VERSION ""

NS_ :

BS_:

BU_: XXX

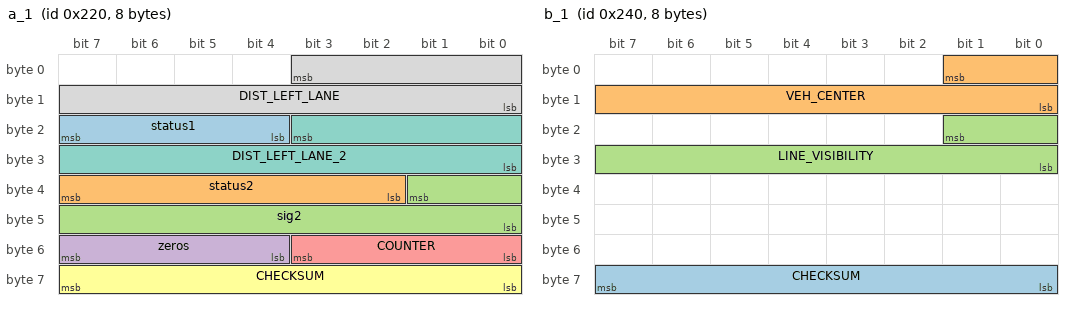
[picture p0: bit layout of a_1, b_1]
BO_ 544 a_1: 8 XXX
 SG_ status1 : 23|4@0+ (1,0) [0|15] "" XXX
 SG_ status2 : 39|6@0+ (1,0) [0|15] "" XXX
 SG_ sig2 : 33|10@0+ (1,0) [0|255] "" XXX
 SG_ zeros : 55|4@0+ (1,0) [0|15] "" XXX
 SG_ COUNTER : 51|4@0+ (1,0) [0|15] "" XXX
 SG_ CHECKSUM : 63|8@0+ (1,0) [0|255] "" XXX
 SG_ DIST_LEFT_LANE_2 : 19|12@0+ (1,0) [0|1] "" XXX
 SG_ DIST_LEFT_LANE : 3|12@0+ (1,0) [0|1] "" XXX

BO_ 576 b_1: 8 XXX
 SG_ CHECKSUM : 63|8@0+ (1,0) [0|255] "" XXX
 SG_ VEH_CENTER : 1|10@0+ (1,0) [0|1] "" XXX
 SG_ LINE_VISIBILITY : 17|10@0+ (1,0) [0|1] "" XXX

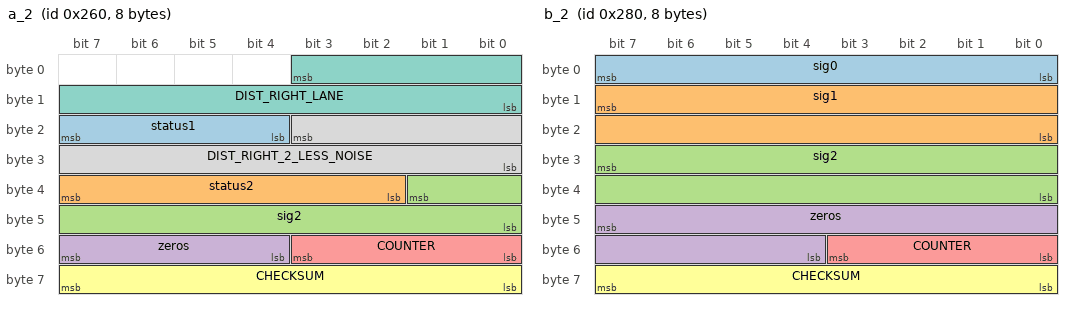
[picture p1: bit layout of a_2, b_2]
BO_ 608 a_2: 8 XXX
 SG_ status1 : 23|4@0+ (1,0) [0|15] "" XXX
 SG_ status2 : 39|6@0+ (1,0) [0|15] "" XXX
 SG_ sig2 : 33|10@0+ (1,0) [0|255] "" XXX
 SG_ zeros : 55|4@0+ (1,0) [0|15] "" XXX
 SG_ COUNTER : 51|4@0+ (1,0) [0|15] "" XXX
 SG_ CHECKSUM : 63|8@0+ (1,0) [0|255] "" XXX
 SG_ DIST_RIGHT_LANE : 3|12@0+ (1,0) [0|1] "" XXX
 SG_ DIST_RIGHT_2_LESS_NOISE : 19|12@0+ (1,0) [0|1] "" XXX

BO_ 640 b_2: 8 XXX
 SG_ sig0 : 7|8@0+ (1,0) [0|255] "" XXX
 SG_ sig1 : 15|16@0+ (1,0) [0|65535] "" XXX
 SG_ sig2 : 31|16@0+ (1,0) [0|255] "" XXX
 SG_ zeros : 47|12@0+ (1,0) [0|255] "" XXX
 SG_ COUNTER : 51|4@0+ (1,0) [0|15] "" XXX
 SG_ CHECKSUM : 63|8@0+ (1,0) [0|255] "" XXX

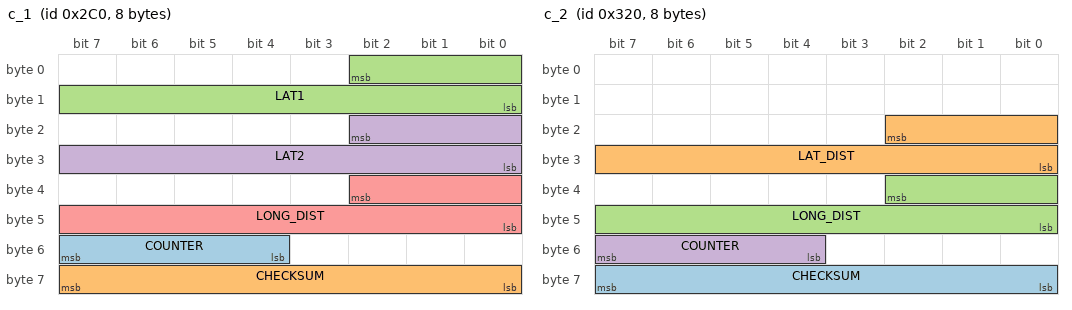
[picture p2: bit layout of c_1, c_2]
BO_ 704 c_1: 8 XXX
 SG_ COUNTER : 55|4@0+ (1,0) [0|15] "" XXX
 SG_ CHECKSUM : 63|8@0+ (1,0) [0|255] "" XXX
 SG_ LAT1 : 2|11@0+ (0.005,-5.12) [0|2047] "m" XXX
 SG_ LAT2 : 18|11@0+ (0.005,-5.12) [0|2047] "m" XXX
 SG_ LONG_DIST : 34|11@0+ (0.046875,0) [0|255] "m" XXX

BO_ 800 c_2: 8 XXX
 SG_ CHECKSUM : 63|8@0+ (1,0) [0|255] "" XXX
 SG_ LAT_DIST : 18|11@0+ (0.005,-5.12) [0|2047] "m" XXX
 SG_ LONG_DIST : 34|11@0+ (0.05,0) [0|255] "m" XXX
 SG_ COUNTER : 55|4@0+ (1,0) [0|15] "" XXX

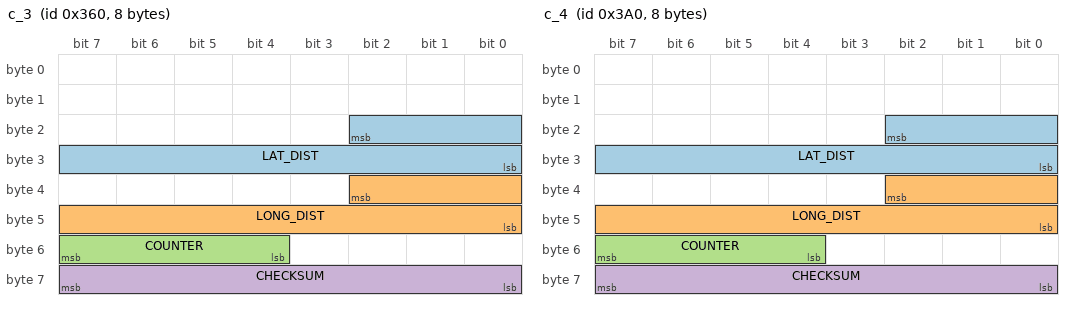
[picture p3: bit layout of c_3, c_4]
BO_ 864 c_3: 8 XXX
 SG_ LAT_DIST : 18|11@0+ (0.005,-5.12) [0|2047] "m" XXX
 SG_ LONG_DIST : 34|11@0+ (0.05,0) [0|255] "m" XXX
 SG_ COUNTER : 55|4@0+ (1,0) [0|15] "" XXX
 SG_ CHECKSUM : 63|8@0+ (1,0) [0|255] "" XXX

BO_ 928 c_4: 8 XXX
 SG_ LAT_DIST : 18|11@0+ (0.005,-5.12) [0|2047] "m" XXX
 SG_ LONG_DIST : 34|11@0+ (0.05,0) [0|255] "m" XXX
 SG_ COUNTER : 55|4@0+ (1,0) [0|15] "" XXX
 SG_ CHECKSUM : 63|8@0+ (1,0) [0|255] "" XXX

BO_ 672 d_1: 8 XXX
 SG_ REL_SPEED : 9|10@0+ (-0.1875,96) [0|1023] "m/s" XXX

BO_ 768 d_2: 8 XXX
 SG_ REL_SPEED : 9|10@0+ (-0.1875,96) [0|1023] "m/s" XXX

BO_ 832 d_3: 8 XXX
 SG_ REL_SPEED : 9|10@0+ (-0.1875,96) [0|1023] "m/s" XXX

BO_ 896 d_4: 8 XXX
 SG_ REL_SPEED : 9|10@0+ (-0.1875,96) [0|1023] "m/s" XXX

CM_ SG_ 544 sig2 "perhaps distance to object. LONG_DIST or REL_ACCEL or REL_SPEED";
CM_ SG_ 576 VEH_CENTER "0x280 when vehicle centered between lines";
CM_ SG_ 608 DIST_RIGHT_LANE "0x800 centered/baseline";
CM_ SG_ 704 LAT1 "positive to the right, negative to the left";
CM_ SG_ 704 LAT2 "positive to the right, negative to the left";
CM_ SG_ 800 LAT_DIST "positive to the right, negative to the left";
CM_ SG_ 864 LAT_DIST "positive to the right, negative to the left";
CM_ SG_ 928 LAT_DIST "positive to the right, negative to the left";
CM_ SG_ 672 REL_SPEED "baseline 0x200";
